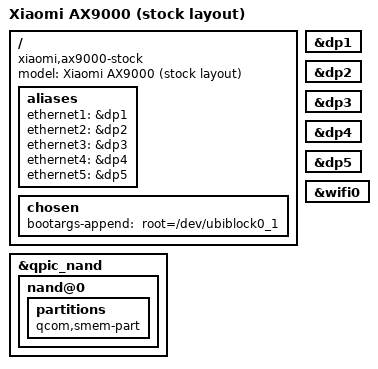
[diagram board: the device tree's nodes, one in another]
// SPDX-License-Identifier: GPL-2.0-or-later OR MIT

#include "ipq8072-ax9000.dts"

/ {
	model = "Xiaomi AX9000 (stock layout)";
	compatible = "xiaomi,ax9000-stock", "qcom,ipq8074";

	aliases {
		/* Aliases as required by u-boot to patch MAC addresses */
		ethernet1 = &dp1;
		ethernet2 = &dp2;
		ethernet3 = &dp3;
		ethernet4 = &dp4;
		ethernet5 = &dp5;
	};

	chosen {
		bootargs-append = " root=/dev/ubiblock0_1";
	};
};

&qpic_nand {
	/delete-node/ partitions;

	nand@0 {
		/delete-node/ partitions;

		partitions {
			compatible = "qcom,smem-part";
		};
	};
};

&dp1 {
	/delete-property/ nvmem-cells;
	/delete-property/ nvmem-cell-names;
};

&dp2 {
	/delete-property/ nvmem-cells;
	/delete-property/ nvmem-cell-names;
};

&dp3 {
	/delete-property/ nvmem-cells;
	/delete-property/ nvmem-cell-names;
};

&dp4 {
	/delete-property/ nvmem-cells;
	/delete-property/ nvmem-cell-names;
};

&dp5 {
	/delete-property/ nvmem-cells;
	/delete-property/ nvmem-cell-names;
};

&wifi0 {
	/delete-property/ nvmem-cells;
	/delete-property/ nvmem-cell-names;
};
